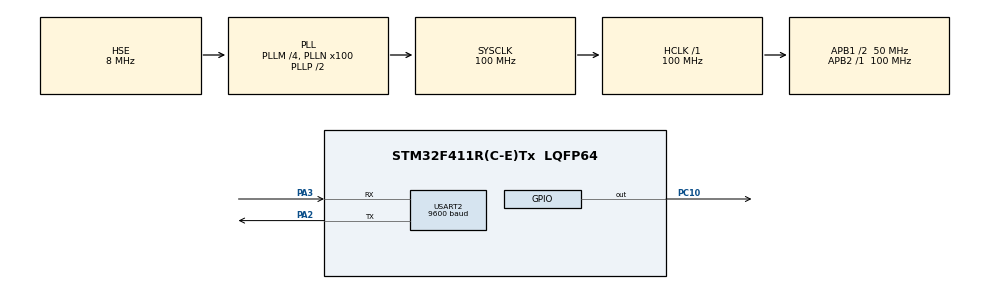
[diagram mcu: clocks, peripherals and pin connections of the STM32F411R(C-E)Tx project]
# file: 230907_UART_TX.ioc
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Dma.Request0=USART2_RX
Dma.Request1=USART2_TX
Dma.USART2_RX.0.Direction=DMA_PERIPH_TO_MEMORY
Dma.USART2_RX.0.FIFOMode=DMA_FIFOMODE_DISABLE
Dma.USART2_RX.0.Instance=DMA1_Stream5
Dma.USART2_RX.0.MemDataAlignment=DMA_MDATAALIGN_BYTE
Dma.USART2_RX.0.MemInc=DMA_MINC_ENABLE
Dma.USART2_RX.0.Mode=DMA_NORMAL
Dma.USART2_RX.0.PeriphDataAlignment=DMA_PDATAALIGN_BYTE
Dma.USART2_RX.0.PeriphInc=DMA_PINC_DISABLE
Dma.USART2_RX.0.Priority=DMA_PRIORITY_LOW
Dma.USART2_TX.1.Direction=DMA_MEMORY_TO_PERIPH
Dma.USART2_TX.1.FIFOMode=DMA_FIFOMODE_DISABLE
Dma.USART2_TX.1.Instance=DMA1_Stream6
Dma.USART2_TX.1.MemDataAlignment=DMA_MDATAALIGN_BYTE
Dma.USART2_TX.1.MemInc=DMA_MINC_ENABLE
Dma.USART2_TX.1.Mode=DMA_NORMAL
Dma.USART2_TX.1.PeriphDataAlignment=DMA_PDATAALIGN_BYTE
Dma.USART2_TX.1.PeriphInc=DMA_PINC_DISABLE
Dma.USART2_TX.1.Priority=DMA_PRIORITY_LOW
Mcu.Family=STM32F4
Mcu.Name=STM32F411R(C-E)Tx
Mcu.Package=LQFP64
NVIC.DMA1_Stream5_IRQn=true\:0\:0\:false\:false\:true\:false\:true\:true
NVIC.DMA1_Stream6_IRQn=true\:0\:0\:false\:false\:true\:false\:true\:true
NVIC.PriorityGroup=NVIC_PRIORITYGROUP_4
NVIC.USART2_IRQn=true\:0\:0\:false\:false\:true\:true\:true\:true
PA13.Mode=Serial_Wire
PA13.Signal=SYS_JTMS-SWDIO
PA14.Mode=Serial_Wire
PA14.Signal=SYS_JTCK-SWCLK
PA2.Mode=Asynchronous
PA2.Signal=USART2_TX
PA3.Mode=Asynchronous
PA3.Signal=USART2_RX
PC10.Signal=GPIO_Output
PH0\ -\ OSC_IN.Mode=HSE-External-Oscillator
PH0\ -\ OSC_IN.Signal=RCC_OSC_IN
PH1\ -\ OSC_OUT.Mode=HSE-External-Oscillator
PH1\ -\ OSC_OUT.Signal=RCC_OSC_OUT
ProjectManager.HeapSize=0x200
ProjectManager.StackSize=0x400
ProjectManager.TargetToolchain=STM32CubeIDE
RCC.48MHZClocksFreq_Value=50000000
RCC.AHBFreq_Value=100000000
RCC.APB1CLKDivider=RCC_HCLK_DIV2
RCC.APB1Freq_Value=50000000
RCC.APB1TimFreq_Value=100000000
RCC.APB2Freq_Value=100000000
RCC.APB2TimFreq_Value=100000000
RCC.CortexFreq_Value=100000000
RCC.HCLKFreq_Value=100000000
RCC.HSE_VALUE=8000000
RCC.HSI_VALUE=16000000
RCC.LSE_VALUE=32768
RCC.PLLM=4
RCC.PLLN=100
RCC.PLLSourceVirtual=RCC_PLLSOURCE_HSE
RCC.SYSCLKFreq_VALUE=100000000
RCC.SYSCLKSource=RCC_SYSCLKSOURCE_PLLCLK
RCC.VCOOutputFreq_Value=200000000
USART2.BaudRate=9600
USART2.VirtualMode=VM_ASYNC
board=custom

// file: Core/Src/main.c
/* USER CODE BEGIN Header */
/**
  ******************************************************************************
  * @file           : main.c
  * @brief          : Main program body
  ******************************************************************************
  * @attention
  *
  * Copyright (c) 2023 STMicroelectronics.
  * All rights reserved.
  *
  * This software is licensed under terms that can be found in the LICENSE file
  * in the root directory of this software component.
  * If no LICENSE file comes with this software, it is provided AS-IS.
  *
  ******************************************************************************
  */
/* USER CODE END Header */
#include "main.h"
#include "dma.h"
#include "usart.h"
#include "gpio.h"

/* USER CODE BEGIN PV */
uint8_t txData[10];
uint8_t led_Count = 0;
/* USER CODE END PV */

void SystemClock_Config(void);
/* USER CODE BEGIN PFP */
void HAL_UART_TxCpltCallback(UART_HandleTypeDef *huart){    // TxCpltCallback: tx completed call back
  // HAL_UART_Transmit_IT(&huart2, txData, sizeof(txData));
}
/* USER CODE END PFP */

int main(void)
{

  /* MCU Configuration--------------------------------------------------------*/
  /* Reset of all peripherals, Initializes the Flash interface and the Systick. */
  HAL_Init();

  /* Configure the system clock */
  SystemClock_Config();

  /* Initialize all configured peripherals */
  MX_GPIO_Init();
  MX_DMA_Init();
  MX_USART2_UART_Init();
  /* USER CODE BEGIN 2 */
  for(int i=0;i<10;i++){
    txData[i]='y';
  }

  HAL_UART_Transmit_IT(&huart2, txData, sizeof(txData));
  /* USER CODE END 2 */

  /* Infinite loop */
  while (1)
  {

    /* USER CODE BEGIN 3 */

//    HAL_UART_Transmit(&huart2, txData, sizeof(txData), 500);
//    HAL_Delay(500);

    HAL_GPIO_TogglePin(GPIOC, GPIO_PIN_10);
    HAL_Delay(200);

    led_Count++;
    if((led_Count%20)==0)
    {
      HAL_UART_Transmit_IT(&huart2, txData, sizeof(txData));
      HAL_UART_Transmit_DMA(&huart2, txData, sizeof(txData));
    }

  }
  /* USER CODE END 3 */
}

void SystemClock_Config(void)
{
  RCC_OscInitTypeDef RCC_OscInitStruct = {0};
  RCC_ClkInitTypeDef RCC_ClkInitStruct = {0};

  /** Configure the main internal regulator output voltage
  */
  __HAL_RCC_PWR_CLK_ENABLE();
  __HAL_PWR_VOLTAGESCALING_CONFIG(PWR_REGULATOR_VOLTAGE_SCALE1);

  /** Initializes the RCC Oscillators according to the specified parameters
  * in the RCC_OscInitTypeDef structure.
  */
  RCC_OscInitStruct.OscillatorType = RCC_OSCILLATORTYPE_HSE;
  RCC_OscInitStruct.HSEState = RCC_HSE_ON;
  RCC_OscInitStruct.PLL.PLLState = RCC_PLL_ON;
  RCC_OscInitStruct.PLL.PLLSource = RCC_PLLSOURCE_HSE;
  RCC_OscInitStruct.PLL.PLLM = 4;
  RCC_OscInitStruct.PLL.PLLN = 100;
  RCC_OscInitStruct.PLL.PLLP = RCC_PLLP_DIV2;
  RCC_OscInitStruct.PLL.PLLQ = 4;
  if (HAL_RCC_OscConfig(&RCC_OscInitStruct) != HAL_OK)
  {
    Error_Handler();
  }

  /** Initializes the CPU, AHB and APB buses clocks
  */
  RCC_ClkInitStruct.ClockType = RCC_CLOCKTYPE_HCLK|RCC_CLOCKTYPE_SYSCLK
                              |RCC_CLOCKTYPE_PCLK1|RCC_CLOCKTYPE_PCLK2;
  RCC_ClkInitStruct.SYSCLKSource = RCC_SYSCLKSOURCE_PLLCLK;
  RCC_ClkInitStruct.AHBCLKDivider = RCC_SYSCLK_DIV1;
  RCC_ClkInitStruct.APB1CLKDivider = RCC_HCLK_DIV2;
  RCC_ClkInitStruct.APB2CLKDivider = RCC_HCLK_DIV1;

  if (HAL_RCC_ClockConfig(&RCC_ClkInitStruct, FLASH_LATENCY_3) != HAL_OK)
  {
    Error_Handler();
  }
}

void Error_Handler(void)
{
  __disable_irq();
  while (1)
  {
  }
}
